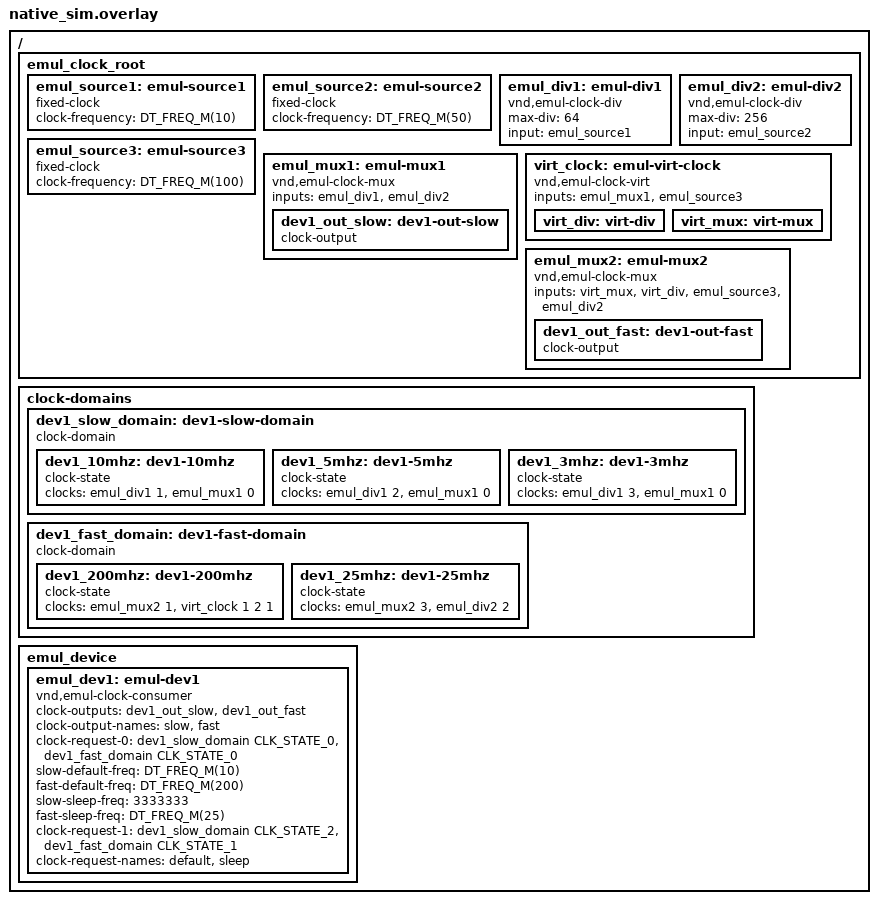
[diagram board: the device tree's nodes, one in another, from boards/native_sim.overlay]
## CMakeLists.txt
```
# SPDX-License-Identifier: Apache-2.0

cmake_minimum_required(VERSION 3.20.0)

find_package(Zephyr REQUIRED HINTS $ENV{ZEPHYR_BASE})
project(clock_management_minimal)

include(${CMAKE_CURRENT_LIST_DIR}/../common/emul_clock_drivers/emul_clock_drivers.cmake)
file(GLOB app_sources src/*.c)
target_sources(app PRIVATE ${app_sources})

# Add custom clock drivers to clock management header list
add_clock_management_header("${CMAKE_CURRENT_LIST_DIR}/../common/emul_clock_drivers/emul_clock_drivers.h")
```

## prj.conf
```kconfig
CONFIG_ZTEST=y
CONFIG_CLOCK_MANAGEMENT=y
CONFIG_CLOCK_MANAGEMENT_RUNTIME=n
CONFIG_CLOCK_MANAGEMENT_SET_RATE=n
CONFIG_CLOCK_MANAGEMENT_KEEP_SLEEP_STATE=y
```

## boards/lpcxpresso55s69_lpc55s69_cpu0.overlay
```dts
/*
 * Copyright (c) 2024 Tenstorrent AI ULC
 * Copyright (c) 2026 Analog Devices, Inc
 *
 * SPDX-License-Identifier: Apache-2.0
 */

#include <freq.h>
#include <zephyr/dt-bindings/clock-management/clock-management.h>

&clock_domains {
	frohf_domain: frohfdiv-domain {
		compatible = "clock-domain";
		#clock-state-cells = <1>;
		/* FROHF clock domain */
		frohf_en: frohfdiv_96m {
			compatible = "clock-state";
			clocks = <&fro_hf 1>;
		};
	};

	sys_clk_domain: sys-clk-domain {
		/delete-node/ sys_clk_144mhz;
		compatible = "clock-domain";
		/* Clock CPU from FROHF, since we will use the PLLs within our testcases */
		sys_clk_96mhz: sys-clk-96mhz {
			compatible = "clock-state";
			clocks = <&ahbclkdiv 1 &mainclksela 3 &mainclkselb 0>;
		};
	};

	/* Define clock states for clockout clock */
	clkout_domain: clkout-domain {
		compatible = "clock-domain";
		#clock-state-cells = <1>;
		clkout_16mhz: clkout-16mhz {
			compatible = "clock-state";
			/* Expect a clock frequency of 16 MHz */
			clocks = <&xtal32m 1 &clk_in_en 1 &pll0clksel 1
				  &pll0_pdec 4 &pll0_directo 0
				  &pll0 8 256 0 31 31 0 0 0
				  &pll0_bypass 0 &clkoutsel 1
				  &clkoutdiv 8>;
		};

		clkout_1mhz: clkout-1mhz {
			compatible = "clock-state";
			/* Expect a clock frequency of 1MHz */
			clocks = <&fro_1m 1 &clkoutsel 4 &clkoutdiv 1>;
		};

		clkout_500mhz: clkout-500mhz {
			compatible = "clock-state";
			/* Expect a clock frequency of 500 KHz */
			clocks = <&xtal32m 1 &clk_in_en 1 &pll0clksel 1
				  &pll0_pdec 4 &pll0_directo 0
				  &pll0 8 256 0 31 31 0 0 0
				  &pll0_bypass 0 &clkoutsel 1
				  &clkoutdiv 256>;
		};
	};

	/* Define clock states for SDIO clock */
	sdioclk_domain: sdioclk-domain {
		compatible = "clock-domain";
		#clock-state-cells = <1>;
		sdioclk_48mhz: sdioclk-48mhz {
			compatible = "clock-state";
			/* Expect a clock frequency of 48 MHz */
			clocks = <&fro_12m 1 &pll1clksel 0
				  &pll1_pdec 4 &pll1_directo 0
				  &pll1 4 128 0 62 31
				  &pll1_bypass 0 &sdioclksel 5
				  &sdioclkdiv 2>;
		};

		sdioclk_24mhz: sdioclk-24mhz {
			compatible = "clock-state";
			/* Expect a clock frequency of 24 MHz */
			clocks = <&fro_12m 1 &pll1clksel 0
				  &pll1_pdec 4 &pll1_directo 0
				  &pll1 4 128 0 62 31
				  &pll1_bypass 0 &sdioclksel 5
				  &sdioclkdiv 4>;
		};

		sdioclk_12mhz: sdioclk-12mhz {
			compatible = "clock-state";
			/* Expect a clock frequency of 12 MHz */
			clocks = <&sdioclksel 3
				  &sdioclkdiv 8>;
		};
	};
};

&cpu0 {
	clock-request-0 = <&sys_clk_domain CLK_STATE_0 &frohf_domain CLK_STATE_0>;
	clock-request-0-locking;
};

/* Disable the SD controller- we are using its clock for this test */
&sdif {
	status = "disabled";
};

/ {
	/* Emulated device clock consumer */
	emul_device {
		emul_dev1: emul-dev1 {
			compatible = "vnd,emul-clock-consumer";
			clock-outputs = <&clkout_clock &sdio_clock>;
			clock-output-names = "slow", "fast";
			clock-request-0 = <&clkout_domain CLK_STATE_0 &sdioclk_domain CLK_STATE_0>;
			slow-default-freq = <DT_FREQ_M(16)>;
			fast-default-freq = <DT_FREQ_M(48)>;
			slow-sleep-freq = <DT_FREQ_M(1)>;
			fast-sleep-freq = <DT_FREQ_M(12)>;
			clock-request-1 = <&clkout_domain CLK_STATE_1 &sdioclk_domain CLK_STATE_2
					   &frohf_domain CLK_STATE_0>;
			clock-request-names = "default", "sleep";
		};
	};
};
```

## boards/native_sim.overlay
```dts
/*
 * Copyright (c) 2024 Tenstorrent AI ULC
 * Copyright (c) 2026 Analog Devices, Inc
 *
 * SPDX-License-Identifier: Apache-2.0
 */

/*
 * Define clock tree with emulated clock nodes.
 * These node labels are chosen so that they won't conflict with SOC clock
 * tree nodelabels. The clock driver implementations used by this tree are
 * stored within the test itself
 */

#include <freq.h>
#include <zephyr/dt-bindings/clock-management/clock-management.h>

/ {
	emul_clock_root {
		emul_source1: emul-source1 {
			compatible = "fixed-clock";
			clock-frequency = <DT_FREQ_M(10)>;
			#clock-cells = <0>;
		};

		emul_source2: emul-source2 {
			compatible = "fixed-clock";
			clock-frequency = <DT_FREQ_M(50)>;
			#clock-cells = <0>;
		};

		emul_div1: emul-div1 {
			compatible = "vnd,emul-clock-div";
			max-div = <64>;
			#clock-cells = <1>;
			input = <&emul_source1>;
		};

		emul_div2: emul-div2 {
			compatible = "vnd,emul-clock-div";
			max-div = <256>;
			#clock-cells = <1>;
			input = <&emul_source2>;
		};

		emul_source3: emul-source3 {
			compatible = "fixed-clock";
			clock-frequency = <DT_FREQ_M(100)>;
			#clock-cells = <0>;
		};

		emul_mux1: emul-mux1 {
			compatible = "vnd,emul-clock-mux";
			inputs = <&emul_div1 &emul_div2>;
			#clock-cells = <1>;

			dev1_out_slow: dev1-out-slow {
				compatible = "clock-output";
				#clock-cells = <0>;
			};
		};

		virt_clock: emul-virt-clock {
			compatible = "vnd,emul-clock-virt";
			#clock-cells = <3>;
			inputs = <&emul_mux1 &emul_source3>;

			virt_div: virt-div {};

			virt_mux: virt-mux {};
		};

		emul_mux2: emul-mux2 {
			compatible = "vnd,emul-clock-mux";
			inputs = <&virt_mux &virt_div &emul_source3 &emul_div2>;
			#clock-cells = <1>;

			dev1_out_fast: dev1-out-fast {
				compatible = "clock-output";
				#clock-cells = <0>;
			};
		};
	};

	clock-domains {
		dev1_slow_domain: dev1-slow-domain {
			compatible = "clock-domain";
			#clock-state-cells = <1>;
			/* Expect a clock frequency of 10 MHz */
			dev1_10mhz: dev1-10mhz {
				compatible = "clock-state";
				clocks = <&emul_div1 1 &emul_mux1 0>;
			};

			/* Expect a clock frequency of 5 MHz */
			dev1_5mhz: dev1-5mhz {
				compatible = "clock-state";
				clocks = <&emul_div1 2 &emul_mux1 0>;
			};

			/* Expect a clock frequency of 3.333333 MHz */
			dev1_3mhz: dev1-3mhz {
				compatible = "clock-state";
				clocks = <&emul_div1 3 &emul_mux1 0>;
			};
		};

		dev1_fast_domain: dev1-fast-domain {
			compatible = "clock-domain";
			#clock-state-cells = <1>;
			/* Expect a clock frequency of 200 MHz */
			dev1_200mhz: dev1-200mhz {
				compatible = "clock-state";
				clocks = <&emul_mux2 1 &virt_clock 1 2 1>;
			};

			/* Expect a clock frequency of 25 MHz */
			dev1_25mhz: dev1-25mhz {
				compatible = "clock-state";
				clocks = <&emul_mux2 3
					  &emul_div2 2>;
			};
		};
	};

	/* Emulated device clock consumer */
	emul_device {
		emul_dev1: emul-dev1 {
			compatible = "vnd,emul-clock-consumer";
			clock-outputs = <&dev1_out_slow &dev1_out_fast>;
			clock-output-names = "slow", "fast";
			clock-request-0 = <&dev1_slow_domain CLK_STATE_0
					   &dev1_fast_domain CLK_STATE_0>;
			slow-default-freq = <DT_FREQ_M(10)>;
			fast-default-freq = <DT_FREQ_M(200)>;
			slow-sleep-freq = <3333333>;
			fast-sleep-freq = <DT_FREQ_M(25)>;
			clock-request-1 = <&dev1_slow_domain CLK_STATE_2
					   &dev1_fast_domain CLK_STATE_1>;
			clock-request-names = "default", "sleep";
		};
	};
};
```

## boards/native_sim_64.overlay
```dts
/*
 * Copyright (c) 2024 Tenstorrent AI ULC
 *
 * SPDX-License-Identifier: Apache-2.0
 */
#include "native_sim.overlay"
```

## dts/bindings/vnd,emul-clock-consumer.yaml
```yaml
# Copyright (c) 2024 Tenstorrent AI UL
#
# SPDX-License-Identifier: Apache-2.0

description: |
  Binding for emulated clock consumer device. This device is used in testing
  to verify that clock states are applied as expected.

compatible: "vnd,emul-clock-consumer"

include: [clock-device.yaml]

properties:
  fast-default-freq:
    type: int
    required: true
    description: |
      Frequency this consumer expects to read when applying default
      clock state for fast output

  fast-sleep-freq:
    type: int
    required: true
    description: |
      Frequency this consumer expects to read when applying sleep
      clock state for fast output

  slow-default-freq:
    type: int
    required: true
    description: |
      Frequency this consumer expects to read when applying default
      clock state for slow output

  slow-sleep-freq:
    type: int
    required: true
    description: |
      Frequency this consumer expects to read when applying sleep
      clock state for slow output
```

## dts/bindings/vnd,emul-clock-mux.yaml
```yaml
# Copyright 2024 NXP
#
# SPDX-License-Identifier: Apache-2.0

description: |
  Binding for emulated clock multiplexer node. This multiplexer will select
  an input clock from the clock nodes provided in the "input" property.
  The node accepts one specifier, the integer index (0 based) of the input
  to select.

compatible: "vnd,emul-clock-mux"

include: [clock-node.yaml]

properties:
  inputs:
    type: phandles
    required: true
    description: |
      Input clock sources available for this multiplexer.

  "#clock-cells":
    const: 1

clock-cells:
  - multiplexer
```

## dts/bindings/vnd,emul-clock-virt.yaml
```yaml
# Copyright (c) 2026 Analog Devices Inc.
#
# SPDX-License-Identifier: Apache-2.0

description: |
  Binding for emulated virtual clock node. This node represents a virtual clock,
  which defines a multiplexer, multiplier, and divider internally. The specifiers
  have the following meaning:
  - multiplexer: selects which input clock mux should use
  - multiplier: selects the multiplier value for mult
  - divider: selects the divider value for div

  The clock is structured like so internally:


   ───┐
      │  ┌─────┐    ┌────┐     ┌─────┐   ┌────────┐
      ┼─►│ mux ├─┬─►│mult├────►│ div ├──►│virt-div│
      │  └─────┘ │  └────┘     └─────┘   └────────┘
   ───┘          │
                 │                       ┌────────┐
                 └──────────────────────►│virt-mux│
                                         └────────┘


  The virtual clock must have child nodes named virt-div and virt-mux, which
  the outputs will be connected to.

compatible: "vnd,emul-clock-virt"

include: [clock-node.yaml]

properties:
  inputs:
    type: phandles
    required: true
    description: |
      Input clock sources available for this multiplexer, connected to mux

  "#clock-cells":
    const: 3

clock-cells:
  - multiplexer
  - multiplier
  - divider
```

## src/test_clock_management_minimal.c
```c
/*
 * Copyright (c) 2024 Tenstorrent AI ULC
 * Copyright (c) 2026 Analog Devices, Inc
 *
 * SPDX-License-Identifier: Apache-2.0
 */
#include <zephyr/ztest.h>
#include <zephyr/drivers/clock_management.h>
#include <zephyr/logging/log.h>

LOG_MODULE_REGISTER(test);

/* Define clock management data */
CLOCK_MANAGEMENT_DT_DEFINE(DT_NODELABEL(emul_dev1));
static const struct clock_management_data *data =
	CLOCK_MANAGEMENT_DT_GET(DT_NODELABEL(emul_dev1));

/* Get references to each clock management output and state */
clock_output_t dev1_slow =
	CLOCK_MANAGEMENT_DT_GET_OUTPUT_BY_NAME(DT_NODELABEL(emul_dev1), slow);
clock_output_t dev1_fast =
	CLOCK_MANAGEMENT_DT_GET_OUTPUT_BY_NAME(DT_NODELABEL(emul_dev1), fast);
clock_request_t default_request = CLOCK_MANAGEMENT_STATE_DEFAULT;
clock_request_t sleep_request = CLOCK_MANAGEMENT_STATE_SLEEP;


/* Runs before every test, resets clocks to default state */
void reset_clock_states(void *unused)
{
	ARG_UNUSED(unused);
	int ret;

	/* Reset clock tree to default state */
	ret = clock_management_request_state(data, default_request);
	zassert_equal(ret, 0, "Failed to apply default clock management request");
	ret = clock_management_get_rate(data, dev1_slow);
	zassert_equal(ret, DT_PROP(DT_NODELABEL(emul_dev1), slow_default_freq),
		      "Failed to apply default clock management state for slow clock");
	ret = clock_management_get_rate(data, dev1_fast);
	zassert_equal(ret, DT_PROP(DT_NODELABEL(emul_dev1), fast_default_freq),
		      "Failed to apply default clock management state for fast clock");
}

ZTEST(clock_management_minimal, test_default_states)
{
	int ret;
	int slow_default = DT_PROP(DT_NODELABEL(emul_dev1), slow_default_freq);
	int fast_default = DT_PROP(DT_NODELABEL(emul_dev1), fast_default_freq);

	/* Apply default clock states for both clock outputs, make sure
	 * that rates match what is expected
	 */
	TC_PRINT("Requesting default clock state\n");

	ret = clock_management_request_state(data, default_request);
	zassert_equal(ret, 0,
		      "Failed to apply default clock management request");
	ret = clock_management_get_rate(data, dev1_slow);
	TC_PRINT("Slow clock default clock rate: %d\n", ret);
	zassert_equal(ret, slow_default,
		      "Slow clock has invalid clock default clock rate");
	ret = clock_management_get_rate(data, dev1_fast);
	TC_PRINT("Fast clock default clock rate: %d\n", ret);
	zassert_equal(ret, fast_default,
		      "Fast clock has invalid clock default clock rate");
}

#ifdef CONFIG_CLOCK_MANAGEMENT_KEEP_SLEEP_STATE
ZTEST(clock_management_minimal, test_sleep_states)
{
	int ret;
	int slow_sleep = DT_PROP(DT_NODELABEL(emul_dev1), slow_sleep_freq);
	int fast_sleep = DT_PROP(DT_NODELABEL(emul_dev1), fast_sleep_freq);

	/* Apply sleep clock states for both clock outputs, make sure
	 * that rates match what is expected
	 */
	TC_PRINT("Requesting sleep clock state\n");

	ret = clock_management_request_state(data, sleep_request);
	zassert_equal(ret, 0,
		      "Failed to apply sleep clock management request");
	ret = clock_management_get_rate(data, dev1_slow);
	TC_PRINT("Slow clock sleep clock rate: %d\n", ret);
	zassert_equal(ret, slow_sleep,
		      "Slow clock has invalid clock sleep clock rate");
	ret = clock_management_get_rate(data, dev1_fast);
	TC_PRINT("Fast clock sleep clock rate: %d\n", ret);
	zassert_equal(ret, fast_sleep,
		      "Fast clock has invalid clock sleep clock rate");
}
#else
ZTEST(clock_management_minimal, test_sleep_states_skipped)
{
	int ret;
	int slow_default = DT_PROP(DT_NODELABEL(emul_dev1), slow_default_freq);
	int fast_default = DT_PROP(DT_NODELABEL(emul_dev1), fast_default_freq);

	/* The sleep request is compiled out when
	 * CONFIG_CLOCK_MANAGEMENT_KEEP_SLEEP_STATE is disabled. Requesting
	 * it must fail with -ENOENT and leave the clocks untouched.
	 */
	TC_PRINT("Requesting skipped sleep clock state\n");

	ret = clock_management_request_state(data, sleep_request);
	zassert_equal(ret, -ENOENT,
		      "Skipped sleep request should return -ENOENT");
	ret = clock_management_get_rate(data, dev1_slow);
	zassert_equal(ret, slow_default,
		      "Slow clock rate should be unchanged");
	ret = clock_management_get_rate(data, dev1_fast);
	zassert_equal(ret, fast_default,
		      "Fast clock rate should be unchanged");
}
#endif /* CONFIG_CLOCK_MANAGEMENT_KEEP_SLEEP_STATE */

ZTEST_SUITE(clock_management_minimal, NULL, NULL, reset_clock_states, NULL, NULL);
```
